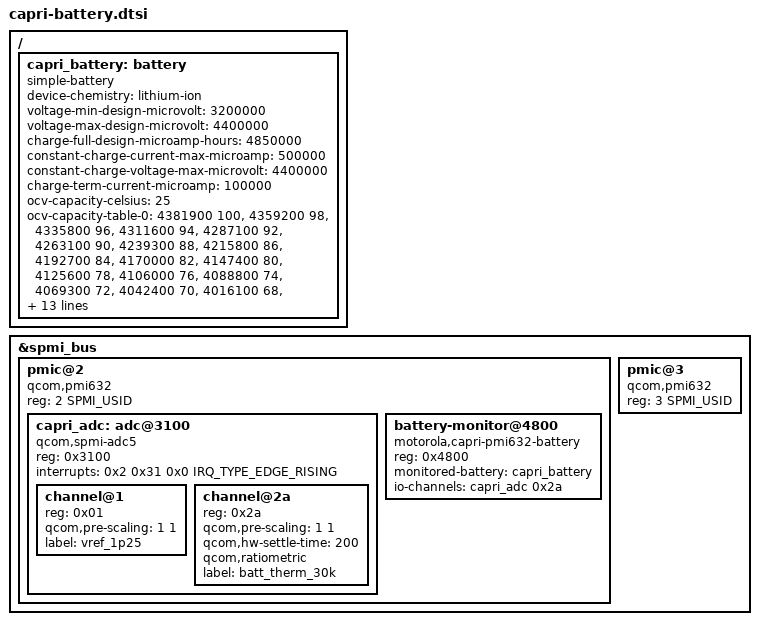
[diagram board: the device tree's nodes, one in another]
// SPDX-License-Identifier: (GPL-2.0+ OR BSD-3-Clause)
/* Factory JK50-SWD-4850MAH battery profile at 25 C. */
/ {
 capri_battery: battery {
  compatible = "simple-battery";
  device-chemistry = "lithium-ion";
  voltage-min-design-microvolt = <3200000>;
  voltage-max-design-microvolt = <4400000>;
  charge-full-design-microamp-hours = <4850000>;
  constant-charge-current-max-microamp = <500000>;
  constant-charge-voltage-max-microvolt = <4400000>;
  charge-term-current-microamp = <100000>;
  ocv-capacity-celsius = <25>;
  ocv-capacity-table-0 =
   <4381900 100>,
   <4359200 98>,
   <4335800 96>,
   <4311600 94>,
   <4287100 92>,
   <4263100 90>,
   <4239300 88>,
   <4215800 86>,
   <4192700 84>,
   <4170000 82>,
   <4147400 80>,
   <4125600 78>,
   <4106000 76>,
   <4088800 74>,
   <4069300 72>,
   <4042400 70>,
   <4016100 68>,
   <3999900 66>,
   <3987900 64>,
   <3974500 62>,
   <3959600 60>,
   <3942100 58>,
   <3916000 56>,
   <3886800 54>,
   <3871700 52>,
   <3863700 50>,
   <3856400 48>,
   <3848400 46>,
   <3840700 44>,
   <3833600 42>,
   <3827000 40>,
   <3820700 38>,
   <3815000 36>,
   <3809600 34>,
   <3805000 32>,
   <3800700 30>,
   <3796400 28>,
   <3792400 26>,
   <3787200 24>,
   <3779000 22>,
   <3768400 20>,
   <3757200 18>,
   <3744600 16>,
   <3729500 14>,
   <3715100 12>,
   <3706100 10>,
   <3703200 9>,
   <3701400 8>,
   <3699600 7>,
   <3695300 6>,
   <3673800 5>,
   <3631300 4>,
   <3574300 3>,
   <3496200 2>,
   <3375100 1>,
   <3000000 0>;
 };
};

&spmi_bus {
 pmic@2 {
  compatible = "qcom,pmi632", "qcom,spmi-pmic";
  reg = <2 SPMI_USID>;
  #address-cells = <1>;
  #size-cells = <0>;
  capri_adc: adc@3100 {
   compatible = "qcom,spmi-adc5";
   reg = <0x3100>;
   #address-cells = <1>;
   #size-cells = <0>;
   #io-channel-cells = <1>;
   interrupts = <0x2 0x31 0x0 IRQ_TYPE_EDGE_RISING>;
   channel@1 {
    reg = <0x01>;
    qcom,pre-scaling = <1 1>;
    label = "vref_1p25";
   };
   channel@2a {
    reg = <0x2a>;
    qcom,pre-scaling = <1 1>;
    qcom,hw-settle-time = <200>;
    qcom,ratiometric;
    label = "batt_therm_30k";
   };
  };
  battery-monitor@4800 {
   compatible = "motorola,capri-pmi632-battery";
   reg = <0x4800>;
   monitored-battery = <&capri_battery>;
   io-channels = <&capri_adc 0x2a>;
   io-channel-names = "batt-therm";
  };
 };
 pmic@3 {
  compatible = "qcom,pmi632", "qcom,spmi-pmic";
  reg = <3 SPMI_USID>;
  #address-cells = <1>;
  #size-cells = <0>;
 };
};
